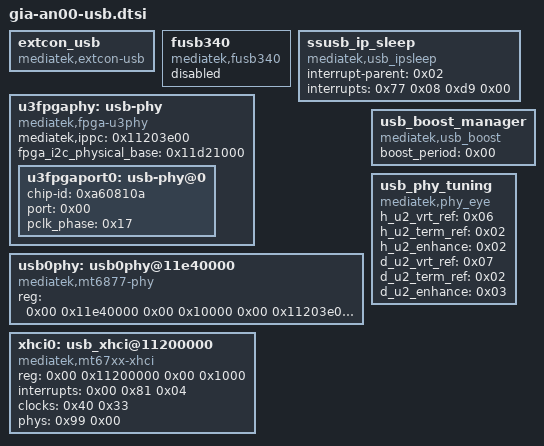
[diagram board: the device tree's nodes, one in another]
// SPDX-License-Identifier: GPL-2.0
/*
 * HONOR GIA-AN00 / MT6877V/ZA 设备树分片
 * 由实机反编译 device.dts 自动还原，节点内容保持原样
 */

/* 8 个顶层节点 */

	extcon_usb: extcon_usb {
			compatible = "mediatek,extcon-usb";
			phandle = <0x9a>;
		};

	fusb340: fusb340 {
			compatible = "mediatek,fusb340";
			status = "disabled";
			phandle = <0x1cf>;
		};

	ssusb_ip_sleep: ssusb_ip_sleep {
			compatible = "mediatek,usb_ipsleep";
			interrupt-parent = <0x02>;
			interrupts = <0x77 0x08 0xd9 0x00>;
			phandle = <0x1d4>;
		};

	u3fpgaphy: usb-phy {
			compatible = "mediatek,fpga-u3phy";
			mediatek,ippc = <0x11203e00>;
			#address-cells = <0x02>;
			#size-cells = <0x02>;
			fpga_i2c_physical_base = <0x11d21000>;
			status = "okay";
			phandle = <0x1bc>;
	
			u3fpgaport0: usb-phy@0 {
				chip-id = <0xa60810a>;
				port = <0x00>;
				pclk_phase = <0x17>;
				#phy-cells = <0x01>;
				phandle = <0x1bd>;
			};
		};

	usb0phy: usb0phy@11e40000 {
			compatible = "mediatek,mt6877-phy";
			reg = <0x00 0x11e40000 0x00 0x10000 0x00 0x11203e00 0x00 0x100>;
			reg-names = "sif_base", "ippc";
			#phy-cells = <0x01>;
			phandle = <0x99>;
		};

	usb_boost_manager {
			compatible = "mediatek,usb_boost";
			boost_period = <0x00>;
		};

	usb_phy_tuning: usb_phy_tuning {
			compatible = "mediatek,phy_eye";
			h_u2_vrt_ref = <0x06>;
			h_u2_term_ref = <0x02>;
			h_u2_enhance = <0x02>;
			d_u2_vrt_ref = <0x07>;
			d_u2_term_ref = <0x02>;
			d_u2_enhance = <0x03>;
			status = "ok";
			phandle = <0x105>;
		};

	xhci0: usb_xhci@11200000 {
			compatible = "mediatek,mt67xx-xhci";
			reg = <0x00 0x11200000 0x00 0x1000>;
			reg-names = "mac";
			interrupts = <0x00 0x81 0x04>;
			interrupt-names = "xhci";
			clocks = <0x40 0x33>;
			clock-names = "sys_ck";
			phys = <0x99 0x00>;
			phy-names = "port0_phy";
			phandle = <0x1bb>;
		};

